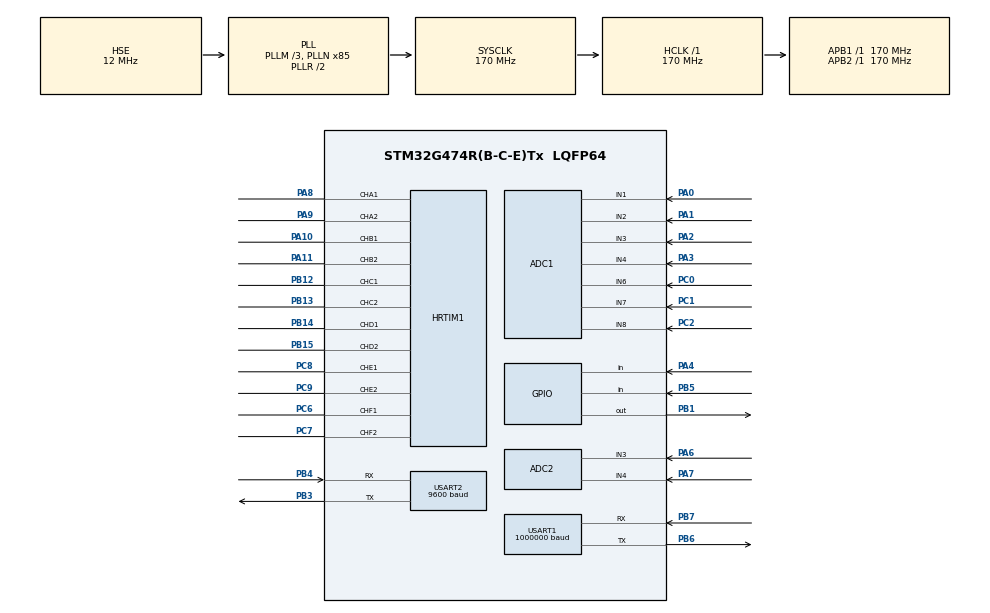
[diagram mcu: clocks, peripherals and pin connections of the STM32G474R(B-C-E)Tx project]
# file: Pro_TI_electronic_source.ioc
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ADC1.Channel-0\#ChannelRegularConversion=ADC_CHANNEL_1
ADC1.Channel-1\#ChannelRegularConversion=ADC_CHANNEL_2
ADC1.Channel-2\#ChannelRegularConversion=ADC_CHANNEL_3
ADC1.Channel-3\#ChannelRegularConversion=ADC_CHANNEL_4
ADC1.Channel-4\#ChannelRegularConversion=ADC_CHANNEL_6
ADC1.Channel-5\#ChannelRegularConversion=ADC_CHANNEL_7
ADC1.Channel-6\#ChannelRegularConversion=ADC_CHANNEL_8
ADC1.ContinuousConvMode=ENABLE
ADC1.DMAContinuousRequests=ENABLE
ADC1.EOCSelection=ADC_EOC_SINGLE_CONV
ADC1.EnableInjectedConversion=DISABLE
ADC1.ExternalTrigConv=ADC_EXTERNALTRIG_HRTIM_TRG1
ADC1.NbrOfConversion=7
ADC1.NbrOfConversionFlag=1
ADC1.OffsetNumber-0\#ChannelRegularConversion=ADC_OFFSET_NONE
ADC1.OffsetNumber-1\#ChannelRegularConversion=ADC_OFFSET_NONE
ADC1.OffsetNumber-2\#ChannelRegularConversion=ADC_OFFSET_NONE
ADC1.OffsetNumber-3\#ChannelRegularConversion=ADC_OFFSET_NONE
ADC1.OffsetNumber-4\#ChannelRegularConversion=ADC_OFFSET_NONE
ADC1.OffsetNumber-5\#ChannelRegularConversion=ADC_OFFSET_NONE
ADC1.OffsetNumber-6\#ChannelRegularConversion=ADC_OFFSET_NONE
ADC1.Overrun=ADC_OVR_DATA_PRESERVED
ADC1.Rank-0\#ChannelRegularConversion=1
ADC1.Rank-1\#ChannelRegularConversion=2
ADC1.Rank-2\#ChannelRegularConversion=3
ADC1.Rank-3\#ChannelRegularConversion=4
ADC1.Rank-4\#ChannelRegularConversion=5
ADC1.Rank-5\#ChannelRegularConversion=6
ADC1.Rank-6\#ChannelRegularConversion=7
ADC1.Rank1_Channel=ADC_CHANNEL_1
ADC1.SamplingTime-0\#ChannelRegularConversion=ADC_SAMPLETIME_24CYCLES_5
ADC1.SamplingTime-1\#ChannelRegularConversion=ADC_SAMPLETIME_24CYCLES_5
ADC1.SamplingTime-2\#ChannelRegularConversion=ADC_SAMPLETIME_24CYCLES_5
ADC1.SamplingTime-3\#ChannelRegularConversion=ADC_SAMPLETIME_24CYCLES_5
ADC1.SamplingTime-4\#ChannelRegularConversion=ADC_SAMPLETIME_24CYCLES_5
ADC1.SamplingTime-5\#ChannelRegularConversion=ADC_SAMPLETIME_24CYCLES_5
ADC1.SamplingTime-6\#ChannelRegularConversion=ADC_SAMPLETIME_24CYCLES_5
ADC1.master=1
ADC2.Channel-2\#ChannelRegularConversion=ADC_CHANNEL_3
ADC2.Channel-3\#ChannelRegularConversion=ADC_CHANNEL_4
ADC2.ContinuousConvMode=ENABLE
ADC2.DMAContinuousRequests=ENABLE
ADC2.ExternalTrigConv=ADC_EXTERNALTRIG_HRTIM_TRG1
ADC2.NbrOfConversion=2
ADC2.NbrOfConversionFlag=1
ADC2.OffsetNumber-2\#ChannelRegularConversion=ADC_OFFSET_NONE
ADC2.OffsetNumber-3\#ChannelRegularConversion=ADC_OFFSET_NONE
ADC2.Rank-2\#ChannelRegularConversion=1
ADC2.Rank-3\#ChannelRegularConversion=2
ADC2.SamplingTime-2\#ChannelRegularConversion=ADC_SAMPLETIME_12CYCLES_5
ADC2.SamplingTime-3\#ChannelRegularConversion=ADC_SAMPLETIME_12CYCLES_5
Dma.ADC1.0.Direction=DMA_PERIPH_TO_MEMORY
Dma.ADC1.0.EventEnable=DISABLE
Dma.ADC1.0.Instance=DMA1_Channel1
Dma.ADC1.0.MemDataAlignment=DMA_MDATAALIGN_HALFWORD
Dma.ADC1.0.MemInc=DMA_MINC_ENABLE
Dma.ADC1.0.Mode=DMA_CIRCULAR
Dma.ADC1.0.PeriphDataAlignment=DMA_PDATAALIGN_HALFWORD
Dma.ADC1.0.PeriphInc=DMA_PINC_DISABLE
Dma.ADC1.0.Polarity=HAL_DMAMUX_REQ_GEN_RISING
Dma.ADC1.0.Priority=DMA_PRIORITY_VERY_HIGH
Dma.ADC1.0.RequestNumber=1
Dma.ADC1.0.SignalID=NONE
Dma.ADC1.0.SyncEnable=DISABLE
Dma.ADC1.0.SyncPolarity=HAL_DMAMUX_SYNC_NO_EVENT
Dma.ADC1.0.SyncRequestNumber=1
Dma.ADC1.0.SyncSignalID=NONE
Dma.ADC2.1.Direction=DMA_PERIPH_TO_MEMORY
Dma.ADC2.1.EventEnable=DISABLE
Dma.ADC2.1.Instance=DMA1_Channel2
Dma.ADC2.1.MemDataAlignment=DMA_MDATAALIGN_HALFWORD
Dma.ADC2.1.MemInc=DMA_MINC_ENABLE
Dma.ADC2.1.Mode=DMA_CIRCULAR
Dma.ADC2.1.PeriphDataAlignment=DMA_PDATAALIGN_HALFWORD
Dma.ADC2.1.PeriphInc=DMA_PINC_DISABLE
Dma.ADC2.1.Polarity=HAL_DMAMUX_REQ_GEN_RISING
Dma.ADC2.1.Priority=DMA_PRIORITY_VERY_HIGH
Dma.ADC2.1.RequestNumber=1
Dma.ADC2.1.SignalID=NONE
Dma.ADC2.1.SyncEnable=DISABLE
Dma.ADC2.1.SyncPolarity=HAL_DMAMUX_SYNC_NO_EVENT
Dma.ADC2.1.SyncRequestNumber=1
Dma.ADC2.1.SyncSignalID=NONE
Dma.Request0=ADC1
Dma.Request1=ADC2
Dma.Request2=USART1_RX
Dma.Request3=USART1_TX
Dma.Request4=USART2_RX
Dma.Request5=USART2_TX
Dma.USART1_RX.2.Direction=DMA_PERIPH_TO_MEMORY
Dma.USART1_RX.2.EventEnable=DISABLE
Dma.USART1_RX.2.Instance=DMA1_Channel3
Dma.USART1_RX.2.MemDataAlignment=DMA_MDATAALIGN_BYTE
Dma.USART1_RX.2.MemInc=DMA_MINC_ENABLE
Dma.USART1_RX.2.Mode=DMA_NORMAL
Dma.USART1_RX.2.PeriphDataAlignment=DMA_PDATAALIGN_BYTE
Dma.USART1_RX.2.PeriphInc=DMA_PINC_DISABLE
Dma.USART1_RX.2.Polarity=HAL_DMAMUX_REQ_GEN_RISING
Dma.USART1_RX.2.Priority=DMA_PRIORITY_LOW
Dma.USART1_RX.2.RequestNumber=1
Dma.USART1_RX.2.SignalID=NONE
Dma.USART1_RX.2.SyncEnable=DISABLE
Dma.USART1_RX.2.SyncPolarity=HAL_DMAMUX_SYNC_NO_EVENT
Dma.USART1_RX.2.SyncRequestNumber=1
Dma.USART1_RX.2.SyncSignalID=NONE
Dma.USART1_TX.3.Direction=DMA_MEMORY_TO_PERIPH
Dma.USART1_TX.3.EventEnable=DISABLE
Dma.USART1_TX.3.Instance=DMA1_Channel4
Dma.USART1_TX.3.MemDataAlignment=DMA_MDATAALIGN_BYTE
Dma.USART1_TX.3.MemInc=DMA_MINC_ENABLE
Dma.USART1_TX.3.Mode=DMA_NORMAL
Dma.USART1_TX.3.PeriphDataAlignment=DMA_PDATAALIGN_BYTE
Dma.USART1_TX.3.PeriphInc=DMA_PINC_DISABLE
Dma.USART1_TX.3.Polarity=HAL_DMAMUX_REQ_GEN_RISING
Dma.USART1_TX.3.Priority=DMA_PRIORITY_LOW
Dma.USART1_TX.3.RequestNumber=1
Dma.USART1_TX.3.SignalID=NONE
Dma.USART1_TX.3.SyncEnable=DISABLE
Dma.USART1_TX.3.SyncPolarity=HAL_DMAMUX_SYNC_NO_EVENT
Dma.USART1_TX.3.SyncRequestNumber=1
Dma.USART1_TX.3.SyncSignalID=NONE
Dma.USART2_RX.4.Direction=DMA_PERIPH_TO_MEMORY
Dma.USART2_RX.4.EventEnable=DISABLE
Dma.USART2_RX.4.Instance=DMA1_Channel5
Dma.USART2_RX.4.MemDataAlignment=DMA_MDATAALIGN_BYTE
Dma.USART2_RX.4.MemInc=DMA_MINC_ENABLE
Dma.USART2_RX.4.Mode=DMA_NORMAL
Dma.USART2_RX.4.PeriphDataAlignment=DMA_PDATAALIGN_BYTE
Dma.USART2_RX.4.PeriphInc=DMA_PINC_DISABLE
Dma.USART2_RX.4.Polarity=HAL_DMAMUX_REQ_GEN_RISING
Dma.USART2_RX.4.Priority=DMA_PRIORITY_LOW
Dma.USART2_RX.4.RequestNumber=1
Dma.USART2_RX.4.SignalID=NONE
Dma.USART2_RX.4.SyncEnable=DISABLE
Dma.USART2_RX.4.SyncPolarity=HAL_DMAMUX_SYNC_NO_EVENT
Dma.USART2_RX.4.SyncRequestNumber=1
Dma.USART2_RX.4.SyncSignalID=NONE
Dma.USART2_TX.5.Direction=DMA_MEMORY_TO_PERIPH
Dma.USART2_TX.5.EventEnable=DISABLE
Dma.USART2_TX.5.Instance=DMA1_Channel6
Dma.USART2_TX.5.MemDataAlignment=DMA_MDATAALIGN_BYTE
Dma.USART2_TX.5.MemInc=DMA_MINC_ENABLE
Dma.USART2_TX.5.Mode=DMA_NORMAL
Dma.USART2_TX.5.PeriphDataAlignment=DMA_PDATAALIGN_BYTE
Dma.USART2_TX.5.PeriphInc=DMA_PINC_DISABLE
Dma.USART2_TX.5.Polarity=HAL_DMAMUX_REQ_GEN_RISING
Dma.USART2_TX.5.Priority=DMA_PRIORITY_LOW
Dma.USART2_TX.5.RequestNumber=1
Dma.USART2_TX.5.SignalID=NONE
Dma.USART2_TX.5.SyncEnable=DISABLE
Dma.USART2_TX.5.SyncPolarity=HAL_DMAMUX_SYNC_NO_EVENT
Dma.USART2_TX.5.SyncRequestNumber=1
Dma.USART2_TX.5.SyncSignalID=NONE
FREERTOS.Tasks01=defaultTask,24,128,StartDefaultTask,Default,NULL,Dynamic,NULL,NULL
HRTIM1.ADCTrigger1_Source1=HRTIM_ADCTRIGGEREVENT13_TIMERA_CMP3
HRTIM1.ADCTrigger_Id1=HRTIM_ADCTRIGGER_1
HRTIM1.ADCTrigger_Id5=__NULL
HRTIM1.CompareUnit1-MasterTimer=HRTIM_COMPAREUNIT_1
HRTIM1.CompareUnit1-Output_TA1TA2=HRTIM_COMPAREUNIT_1
HRTIM1.CompareUnit1-Output_TB1TB2=HRTIM_COMPAREUNIT_1
HRTIM1.CompareUnit1-Output_TC1TC2=HRTIM_COMPAREUNIT_1
HRTIM1.CompareUnit1-Output_TD1TD2=HRTIM_COMPAREUNIT_1
HRTIM1.CompareUnit1-Output_TE1TE2=HRTIM_COMPAREUNIT_1
HRTIM1.CompareUnit1-Output_TF1TF2=HRTIM_COMPAREUNIT_1
HRTIM1.CompareUnit2-MasterTimer=HRTIM_COMPAREUNIT_2
HRTIM1.CompareUnit2-Output_TA1TA2=__NULL
HRTIM1.CompareUnit2-Output_TC1TC2=__NULL
HRTIM1.CompareUnit2-Output_TD1TD2=__NULL
HRTIM1.CompareUnit3-MasterTimer=HRTIM_COMPAREUNIT_3
HRTIM1.CompareUnit3-Output_TA1TA2=HRTIM_COMPAREUNIT_3
HRTIM1.CompareUnit4-MasterTimer=HRTIM_COMPAREUNIT_4
HRTIM1.CompareValue1-MasterTimer=10000
HRTIM1.CompareValue1-Output_TA1TA2=13600
HRTIM1.CompareValue1-Output_TB1TB2=13600
HRTIM1.CompareValue1-Output_TC1TC2=13600
HRTIM1.CompareValue1-Output_TD1TD2=13600
HRTIM1.CompareValue1-Output_TE1TE2=13600
HRTIM1.CompareValue1-Output_TF1TF2=13600
HRTIM1.CompareValue2-MasterTimer=20000
HRTIM1.CompareValue3-MasterTimer=30000
HRTIM1.CompareValue3-Output_TA1TA2=27200
HRTIM1.CompareValue4-MasterTimer=40000
HRTIM1.DeadTimeInsertion-Output_TA1TA2=HRTIM_TIMDEADTIMEINSERTION_ENABLED
HRTIM1.DeadTimeInsertion-Output_TB1TB2=HRTIM_TIMDEADTIMEINSERTION_ENABLED
HRTIM1.DeadTimeInsertion-Output_TC1TC2=HRTIM_TIMDEADTIMEINSERTION_ENABLED
HRTIM1.DeadTimeInsertion-Output_TD1TD2=HRTIM_TIMDEADTIMEINSERTION_ENABLED
HRTIM1.DeadTimeInsertion-Output_TE1TE2=HRTIM_TIMDEADTIMEINSERTION_ENABLED
HRTIM1.DeadTimeInsertion-Output_TF1TF2=HRTIM_TIMDEADTIMEINSERTION_ENABLED
HRTIM1.FallingValue-Output_TA1TA2=34
HRTIM1.FallingValue-Output_TB1TB2=34
HRTIM1.FallingValue-Output_TC1TC2=34
HRTIM1.FallingValue-Output_TD1TD2=34
HRTIM1.FallingValue-Output_TE1TE2=34
HRTIM1.FallingValue-Output_TF1TF2=34
HRTIM1.GreaterCMP1_TB=HRTIM_TIMERGTCMP1_EQUAL
HRTIM1.InterleavedMode-MasterTimer=HRTIM_INTERLEAVED_MODE_DISABLED
HRTIM1.InterleavedMode-Output_TD1TD2=HRTIM_INTERLEAVED_MODE_DISABLED
HRTIM1.InterruptRequests1-Output_TA1TA2=HRTIM_TIM_IT_REP
HRTIM1.InterruptRequests1-Output_TB1TB2=HRTIM_TIM_IT_REP
HRTIM1.ModeTimeBase-Output_TA1TA2=HRTIM_MODE_SINGLESHOT_RETRIGGERABLE
HRTIM1.ModeTimeBase-Output_TB1TB2=HRTIM_MODE_SINGLESHOT_RETRIGGERABLE
HRTIM1.ModeTimeBase-Output_TC1TC2=HRTIM_MODE_SINGLESHOT_RETRIGGERABLE
HRTIM1.ModeTimeBase-Output_TD1TD2=HRTIM_MODE_SINGLESHOT_RETRIGGERABLE
HRTIM1.ModeTimeBase-Output_TE1TE2=HRTIM_MODE_SINGLESHOT_RETRIGGERABLE
HRTIM1.ModeTimeBase-Output_TF1TF2=HRTIM_MODE_SINGLESHOT_RETRIGGERABLE
HRTIM1.NumberADCTriggerSource1=1
HRTIM1.NumberInterruptRequests-Output_TA1TA2=1
HRTIM1.NumberInterruptRequests-Output_TB1TB2=1
HRTIM1.NumberResetSource1-Output_TA1TA2=2
HRTIM1.NumberResetSource1-Output_TB1TB2=2
HRTIM1.NumberResetSource1-Output_TC1TC2=2
HRTIM1.NumberResetSource1-Output_TD1TD2=2
HRTIM1.NumberResetSource1-Output_TE1TE2=2
HRTIM1.NumberResetSource1-Output_TF1TF2=2
HRTIM1.NumberResetTrigger-Output_TA1TA2=1
HRTIM1.NumberResetTrigger-Output_TB1TB2=1
HRTIM1.NumberResetTrigger-Output_TC1TC2=1
HRTIM1.NumberResetTrigger-Output_TD1TD2=1
HRTIM1.NumberResetTrigger-Output_TE1TE2=1
HRTIM1.NumberResetTrigger-Output_TF1TF2=1
HRTIM1.NumberSetSource1-Output_TA1TA2=1
HRTIM1.NumberSetSource1-Output_TB1TB2=1
HRTIM1.NumberSetSource1-Output_TC1TC2=1
HRTIM1.NumberSetSource1-Output_TD1TD2=1
HRTIM1.NumberSetSource1-Output_TE1TE2=1
HRTIM1.NumberSetSource1-Output_TF1TF2=1
HRTIM1.NumberUpdateTrigger-Output_TC1TC2=0
HRTIM1.NumberUpdateTrigger-Output_TD1TD2=0
HRTIM1.ORingUpdateSource_ADCTrigger1=HRTIM_ADCTRIGGERUPDATE_TIMER_A
HRTIM1.Periode_MASTER=54400
HRTIM1.Periode_TA=54400
HRTIM1.Periode_TB=54400
HRTIM1.Periode_TC=54400
HRTIM1.Periode_TD=54400
HRTIM1.Periode_TE=54400
HRTIM1.Periode_TF=54400
HRTIM1.Polarity1-Output_TD1TD2=HRTIM_OUTPUTPOLARITY_HIGH
HRTIM1.Polarity2-Output_TD1TD2=HRTIM_OUTPUTPOLARITY_HIGH
HRTIM1.PreloadEnable-MasterTimer=HRTIM_PRELOAD_ENABLED
HRTIM1.PreloadEnable-Output_TA1TA2=HRTIM_PRELOAD_ENABLED
HRTIM1.PreloadEnable-Output_TB1TB2=HRTIM_PRELOAD_ENABLED
HRTIM1.PreloadEnable-Output_TC1TC2=HRTIM_PRELOAD_ENABLED
HRTIM1.PreloadEnable-Output_TD1TD2=HRTIM_PRELOAD_ENABLED
HRTIM1.PreloadEnable-Output_TE1TE2=HRTIM_PRELOAD_ENABLED
HRTIM1.PreloadEnable-Output_TF1TF2=HRTIM_PRELOAD_ENABLED
HRTIM1.PrescalerDead-Output_TA1TA2=HRTIM_TIMDEADTIME_PRESCALERRATIO_DIV1
HRTIM1.PrescalerDead-Output_TB1TB2=HRTIM_TIMDEADTIME_PRESCALERRATIO_DIV1
HRTIM1.PrescalerDead-Output_TC1TC2=HRTIM_TIMDEADTIME_PRESCALERRATIO_DIV1
HRTIM1.PrescalerDead-Output_TD1TD2=HRTIM_TIMDEADTIME_PRESCALERRATIO_DIV1
HRTIM1.PrescalerDead-Output_TE1TE2=HRTIM_TIMDEADTIME_PRESCALERRATIO_DIV1
HRTIM1.PrescalerDead-Output_TF1TF2=HRTIM_TIMDEADTIME_PRESCALERRATIO_DIV1
HRTIM1.PrescalerRatio_MASTER=HRTIM_PRESCALERRATIO_MUL8
HRTIM1.PrescalerRatio_TA=HRTIM_PRESCALERRATIO_MUL16
HRTIM1.PrescalerRatio_TB=HRTIM_PRESCALERRATIO_MUL16
HRTIM1.PrescalerRatio_TC=HRTIM_PRESCALERRATIO_MUL16
HRTIM1.PrescalerRatio_TD=HRTIM_PRESCALERRATIO_MUL16
HRTIM1.PrescalerRatio_TE=HRTIM_PRESCALERRATIO_MUL16
HRTIM1.PrescalerRatio_TF=HRTIM_PRESCALERRATIO_MUL16
HRTIM1.RepetitionCounter-MasterTimer=0
HRTIM1.RepetitionCounter-Output_TA1TA2=0
HRTIM1.RepetitionCounter-Output_TB1TB2=0
HRTIM1.RepetitionCounter-Output_TC1TC2=0
HRTIM1.RepetitionCounter-Output_TD1TD2=0
HRTIM1.RepetitionCounter-Output_TE1TE2=0
HRTIM1.RepetitionCounter-Output_TF1TF2=0
HRTIM1.RepetitionUpdate-MasterTimer=HRTIM_UPDATEONREPETITION_ENABLED
HRTIM1.RepetitionUpdate-Output_TA1TA2=HRTIM_UPDATEONREPETITION_ENABLED
HRTIM1.RepetitionUpdate-Output_TB1TB2=HRTIM_UPDATEONREPETITION_ENABLED
HRTIM1.RepetitionUpdate-Output_TC1TC2=HRTIM_UPDATEONREPETITION_ENABLED
HRTIM1.RepetitionUpdate-Output_TD1TD2=HRTIM_UPDATEONREPETITION_ENABLED
HRTIM1.RepetitionUpdate-Output_TE1TE2=HRTIM_UPDATEONREPETITION_ENABLED
HRTIM1.RepetitionUpdate-Output_TF1TF2=HRTIM_UPDATEONREPETITION_ENABLED
HRTIM1.ResetOutput1_Source1-Output_TA1TA2=HRTIM_OUTPUTRESET_MASTERPER
HRTIM1.ResetOutput1_Source1-Output_TB1TB2=HRTIM_OUTPUTRESET_MASTERCMP1
HRTIM1.ResetOutput1_Source1-Output_TC1TC2=HRTIM_OUTPUTRESET_MASTERCMP2
HRTIM1.ResetOutput1_Source1-Output_TD1TD2=HRTIM_OUTPUTRESET_MASTERCMP3
HRTIM1.ResetOutput1_Source1-Output_TE1TE2=HRTIM_OUTPUTRESET_MASTERCMP4
HRTIM1.ResetOutput1_Source1-Output_TF1TF2=HRTIM_OUTPUTRESET_MASTERPER
HRTIM1.ResetOutput1_Source2-Output_TA1TA2=HRTIM_OUTPUTRESET_TIMCMP1
HRTIM1.ResetOutput1_Source2-Output_TB1TB2=HRTIM_OUTPUTRESET_TIMCMP1
HRTIM1.ResetOutput1_Source2-Output_TC1TC2=HRTIM_OUTPUTRESET_TIMCMP1
HRTIM1.ResetOutput1_Source2-Output_TD1TD2=HRTIM_OUTPUTRESET_TIMCMP1
HRTIM1.ResetOutput1_Source2-Output_TE1TE2=HRTIM_OUTPUTRESET_TIMCMP1
HRTIM1.ResetOutput1_Source2-Output_TF1TF2=HRTIM_OUTPUTRESET_TIMCMP1
HRTIM1.ResetTrigger1-Output_TA1TA2=HRTIM_TIMRESETTRIGGER_MASTER_PER
HRTIM1.ResetTrigger1-Output_TB1TB2=HRTIM_TIMRESETTRIGGER_MASTER_CMP1
HRTIM1.ResetTrigger1-Output_TC1TC2=HRTIM_TIMRESETTRIGGER_MASTER_CMP2
HRTIM1.ResetTrigger1-Output_TD1TD2=HRTIM_TIMRESETTRIGGER_MASTER_CMP3
HRTIM1.ResetTrigger1-Output_TE1TE2=HRTIM_TIMRESETTRIGGER_MASTER_CMP4
HRTIM1.ResetTrigger1-Output_TF1TF2=HRTIM_TIMRESETTRIGGER_MASTER_PER
HRTIM1.RisingValue-Output_TA1TA2=34
HRTIM1.RisingValue-Output_TB1TB2=34
HRTIM1.RisingValue-Output_TC1TC2=34
HRTIM1.RisingValue-Output_TD1TD2=34
HRTIM1.RisingValue-Output_TE1TE2=34
HRTIM1.RisingValue-Output_TF1TF2=34
HRTIM1.SetOutput1_Source1-Output_TA1TA2=HRTIM_OUTPUTSET_TIMCMP1
HRTIM1.SetOutput1_Source1-Output_TB1TB2=HRTIM_OUTPUTSET_TIMCMP1
HRTIM1.SetOutput1_Source1-Output_TC1TC2=HRTIM_OUTPUTSET_TIMCMP1
HRTIM1.SetOutput1_Source1-Output_TD1TD2=HRTIM_OUTPUTSET_TIMCMP1
HRTIM1.SetOutput1_Source1-Output_TE1TE2=HRTIM_OUTPUTSET_TIMCMP1
HRTIM1.SetOutput1_Source1-Output_TF1TF2=HRTIM_OUTPUTSET_TIMCMP1
HRTIM1.UpDownMode-Output_TA1TA2=HRTIM_TIMERUPDOWNMODE_UPDOWN
HRTIM1.UpDownMode-Output_TB1TB2=HRTIM_TIMERUPDOWNMODE_UPDOWN
HRTIM1.UpDownMode-Output_TC1TC2=HRTIM_TIMERUPDOWNMODE_UPDOWN
HRTIM1.UpDownMode-Output_TD1TD2=HRTIM_TIMERUPDOWNMODE_UPDOWN
HRTIM1.UpDownMode-Output_TE1TE2=HRTIM_TIMERUPDOWNMODE_UPDOWN
HRTIM1.UpDownMode-Output_TF1TF2=HRTIM_TIMERUPDOWNMODE_UPDOWN
HRTIM1.postscaler1=9
Mcu.Family=STM32G4
Mcu.Name=STM32G474R(B-C-E)Tx
Mcu.Package=LQFP64
NVIC.ADC1_2_IRQn=true\:5\:0\:true\:false\:true\:true\:true\:true\:true
NVIC.DMA1_Channel1_IRQn=true\:5\:0\:false\:false\:true\:true\:false\:true\:true
NVIC.DMA1_Channel2_IRQn=true\:5\:0\:false\:false\:true\:true\:false\:true\:true
NVIC.DMA1_Channel3_IRQn=true\:5\:0\:false\:false\:true\:true\:false\:true\:true
NVIC.DMA1_Channel4_IRQn=true\:5\:0\:false\:false\:true\:true\:false\:true\:true
NVIC.DMA1_Channel5_IRQn=true\:5\:0\:false\:false\:true\:true\:false\:true\:true
NVIC.DMA1_Channel6_IRQn=true\:5\:0\:false\:false\:true\:true\:false\:true\:true
NVIC.HRTIM1_TIMA_IRQn=true\:5\:0\:true\:false\:true\:true\:true\:true\:true
NVIC.PriorityGroup=NVIC_PRIORITYGROUP_4
NVIC.TIM2_IRQn=true\:6\:0\:true\:false\:true\:true\:true\:true\:true
NVIC.USART1_IRQn=true\:5\:0\:false\:false\:true\:true\:true\:true\:true
NVIC.USART2_IRQn=true\:5\:0\:false\:false\:true\:true\:true\:true\:true
PA0.Mode=IN1-Single-Ended
PA0.Signal=ADC1_IN1
PA1.Mode=IN2-Single-Ended
PA1.Signal=ADC1_IN2
PA10.Mode=Output_TB1TB2
PA10.Signal=HRTIM1_CHB1
PA11.Mode=Output_TB1TB2
PA11.Signal=HRTIM1_CHB2
PA13.Mode=Serial_Wire
PA13.Signal=SYS_JTMS-SWDIO
PA14.Mode=Serial_Wire
PA14.Signal=SYS_JTCK-SWCLK
PA2.Mode=IN3-Single-Ended
PA2.Signal=ADC1_IN3
PA3.Mode=IN4-Single-Ended
PA3.Signal=ADC1_IN4
PA4.GPIO_PuPd=GPIO_PULLUP
PA4.Signal=GPIO_Input
PA6.Mode=IN3-Single-Ended
PA6.Signal=ADC2_IN3
PA7.Mode=IN4-Single-Ended
PA7.Signal=ADC2_IN4
PA8.Mode=Output_TA1TA2
PA8.Signal=HRTIM1_CHA1
PA9.Mode=Output_TA1TA2
PA9.Signal=HRTIM1_CHA2
PB1.GPIO_PuPd=GPIO_PULLUP
PB1.Signal=GPIO_Output
PB12.Mode=Output_TC1TC2
PB12.Signal=HRTIM1_CHC1
PB13.Mode=Output_TC1TC2
PB13.Signal=HRTIM1_CHC2
PB14.Mode=Output_TD1TD2
PB14.Signal=HRTIM1_CHD1
PB15.Mode=Output_TD1TD2
PB15.Signal=HRTIM1_CHD2
PB3.Mode=Asynchronous
PB3.Signal=USART2_TX
PB4.Mode=Asynchronous
PB4.Signal=USART2_RX
PB5.GPIO_PuPd=GPIO_PULLUP
PB5.Signal=GPIO_Input
PB6.Mode=Asynchronous
PB6.Signal=USART1_TX
PB7.Mode=Asynchronous
PB7.Signal=USART1_RX
PC0.Mode=IN6-Single-Ended
PC0.Signal=ADC1_IN6
PC1.Mode=IN7-Single-Ended
PC1.Signal=ADC1_IN7
PC2.Mode=IN8-Single-Ended
PC2.Signal=ADC1_IN8
PC6.Mode=Output_TF1TF2
PC6.Signal=HRTIM1_CHF1
PC7.Mode=Output_TF1TF2
PC7.Signal=HRTIM1_CHF2
PC8.Mode=Output_TE1TE2
PC8.Signal=HRTIM1_CHE1
PC9.Mode=Output_TE1TE2
PC9.Signal=HRTIM1_CHE2
PF0-OSC_IN.Mode=HSE-External-Oscillator
PF0-OSC_IN.Signal=RCC_OSC_IN
PF1-OSC_OUT.Mode=HSE-External-Oscillator
PF1-OSC_OUT.Signal=RCC_OSC_OUT
ProjectManager.HeapSize=0x200
ProjectManager.StackSize=0x400
ProjectManager.TargetToolchain=CMake
RCC.ADC12Freq_Value=170000000
RCC.ADC345Freq_Value=170000000
RCC.AHBFreq_Value=170000000
RCC.APB1Freq_Value=170000000
RCC.APB1TimFreq_Value=170000000
RCC.APB2Freq_Value=170000000
RCC.APB2TimFreq_Value=170000000
RCC.CortexFreq_Value=170000000
RCC.EXTERNAL_CLOCK_VALUE=12288000
RCC.HCLKFreq_Value=170000000
RCC.HSE_VALUE=12000000
RCC.HSI48_VALUE=48000000
RCC.HSI_VALUE=16000000
RCC.LSE_VALUE=32768
RCC.PLLM=RCC_PLLM_DIV3
RCC.PLLN=85
RCC.PLLSourceVirtual=RCC_PLLSOURCE_HSE
RCC.SYSCLKFreq_VALUE=170000000
RCC.SYSCLKSource=RCC_SYSCLKSOURCE_PLLCLK
RCC.USBFreq_Value=170000000
RCC.VCOOutputFreq_Value=340000000
STMicroelectronics.X-CUBE-ALGOBUILD.1.4.0.LibraryCcDSPOoLibraryJjDSPOoLibrary=true
TIM2.PeriodNoDither=1000-1
TIM2.Prescaler=170-1
USART1.BaudRate=1000000
USART1.VirtualMode-Asynchronous=VM_ASYNC
USART2.BaudRate=9600
USART2.VirtualMode-Asynchronous=VM_ASYNC
VP_CORDIC_VS_CORDIC.Mode=CORDIC_Activate
VP_FREERTOS_VS_CMSIS_V2.Mode=CMSIS_V2
VP_HRTIM1_VS_hrtimMasterTimerNoOutput.Mode=MasterTimer
VP_STMicroelectronics.X-CUBE-ALGOBUILD_VS_DSPOoLibraryJjLibrary_1.4.0_1.4.0.Mode=DSPOoLibraryJjLibrary
VP_SYS_VS_DBSignals.Mode=DisableDeadBatterySignals
VP_TIM1_VS_ClockSourceINT.Mode=Internal
VP_TIM2_VS_ClockSourceINT.Mode=Internal
VP_TIM3_VS_ClockSourceINT.Mode=Internal
board=custom

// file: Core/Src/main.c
/* USER CODE BEGIN Header */
/**
  ******************************************************************************
  * @file           : main.c
  * @brief          : Main program body
  ******************************************************************************
  * @attention
  *
  * Copyright (c) 2025 STMicroelectronics.
  * All rights reserved.
  *
  * This software is licensed under terms that can be found in the LICENSE file
  * in the root directory of this software component.
  * If no LICENSE file comes with this software, it is provided AS-IS.
  *
  ******************************************************************************
  */
/* USER CODE END Header */
#include "main.h"
#include "cmsis_os.h"
#include "adc.h"
#include "cordic.h"
#include "dma.h"
#include "hrtim.h"
#include "tim.h"
#include "usart.h"
#include "gpio.h"

void SystemClock_Config(void);
void MX_FREERTOS_Init(void);

int main(void)
{

  /* MCU Configuration--------------------------------------------------------*/

  /* Reset of all peripherals, Initializes the Flash interface and the Systick. */
  HAL_Init();

  /* Configure the system clock */
  SystemClock_Config();

  /* Initialize all configured peripherals */
  MX_GPIO_Init();
  MX_DMA_Init();
  MX_HRTIM1_Init();
  MX_TIM2_Init();
  MX_ADC1_Init();
  MX_ADC2_Init();
  MX_TIM3_Init();
  MX_TIM1_Init();
  MX_CORDIC_Init();
  MX_USART1_UART_Init();
  MX_USART2_UART_Init();

  /* Init scheduler */
  osKernelInitialize();  /* Call init function for freertos objects (in cmsis_os2.c) */
  MX_FREERTOS_Init();

  /* Start scheduler */
  osKernelStart();

  /* We should never get here as control is now taken by the scheduler */

  /* Infinite loop */
  while (1)
  {

  }
}

void SystemClock_Config(void)
{
  RCC_OscInitTypeDef RCC_OscInitStruct = {0};
  RCC_ClkInitTypeDef RCC_ClkInitStruct = {0};

  /** Configure the main internal regulator output voltage
  */
  HAL_PWREx_ControlVoltageScaling(PWR_REGULATOR_VOLTAGE_SCALE1_BOOST);

  /** Initializes the RCC Oscillators according to the specified parameters
  * in the RCC_OscInitTypeDef structure.
  */
  RCC_OscInitStruct.OscillatorType = RCC_OSCILLATORTYPE_HSE;
  RCC_OscInitStruct.HSEState = RCC_HSE_ON;
  RCC_OscInitStruct.PLL.PLLState = RCC_PLL_ON;
  RCC_OscInitStruct.PLL.PLLSource = RCC_PLLSOURCE_HSE;
  RCC_OscInitStruct.PLL.PLLM = RCC_PLLM_DIV3;
  RCC_OscInitStruct.PLL.PLLN = 85;
  RCC_OscInitStruct.PLL.PLLP = RCC_PLLP_DIV2;
  RCC_OscInitStruct.PLL.PLLQ = RCC_PLLQ_DIV2;
  RCC_OscInitStruct.PLL.PLLR = RCC_PLLR_DIV2;
  if (HAL_RCC_OscConfig(&RCC_OscInitStruct) != HAL_OK)
  {
    Error_Handler();
  }

  /** Initializes the CPU, AHB and APB buses clocks
  */
  RCC_ClkInitStruct.ClockType = RCC_CLOCKTYPE_HCLK|RCC_CLOCKTYPE_SYSCLK
                              |RCC_CLOCKTYPE_PCLK1|RCC_CLOCKTYPE_PCLK2;
  RCC_ClkInitStruct.SYSCLKSource = RCC_SYSCLKSOURCE_PLLCLK;
  RCC_ClkInitStruct.AHBCLKDivider = RCC_SYSCLK_DIV1;
  RCC_ClkInitStruct.APB1CLKDivider = RCC_HCLK_DIV1;
  RCC_ClkInitStruct.APB2CLKDivider = RCC_HCLK_DIV1;

  if (HAL_RCC_ClockConfig(&RCC_ClkInitStruct, FLASH_LATENCY_4) != HAL_OK)
  {
    Error_Handler();
  }
}

void Error_Handler(void)
{
  __disable_irq();
  while (1)
  {
  }
}

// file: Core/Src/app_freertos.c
/* USER CODE BEGIN Header */
/**
  ******************************************************************************
  * File Name          : app_freertos.c
  * Description        : Code for freertos applications
  ******************************************************************************
  * @attention
  *
  * Copyright (c) 2025 STMicroelectronics.
  * All rights reserved.
  *
  * This software is licensed under terms that can be found in the LICENSE file
  * in the root directory of this software component.
  * If no LICENSE file comes with this software, it is provided AS-IS.
  *
  ******************************************************************************
  */
/* USER CODE END Header */

#include "FreeRTOS.h"
#include "task.h"
#include "main.h"
#include "cmsis_os.h"

/* USER CODE BEGIN Includes */
#include "Thread_Adjust.h"

/* USER CODE END Includes */

/* Definitions for defaultTask */
osThreadId_t defaultTaskHandle;
const osThreadAttr_t defaultTask_attributes = {
  .name = "defaultTask",
  .priority = (osPriority_t) osPriorityNormal,
  .stack_size = 128 * 4
};

void StartDefaultTask(void *argument);

void MX_FREERTOS_Init(void); /* (MISRA C 2004 rule 8.1) */

void MX_FREERTOS_Init(void) {

  /* Create the thread(s) */
  /* creation of defaultTask */
  defaultTaskHandle = osThreadNew(StartDefaultTask, NULL, &defaultTask_attributes);

  /* USER CODE BEGIN RTOS_THREADS */
  /* add threads, ... */
    xTaskCreate(Thread_Adjust, "Thread_Adjust", 512, NULL, osPriorityRealtime, NULL);
  /* USER CODE END RTOS_THREADS */

}

void StartDefaultTask(void *argument)
{
  for(;;)
  {
    osDelay(1);
  }
}
